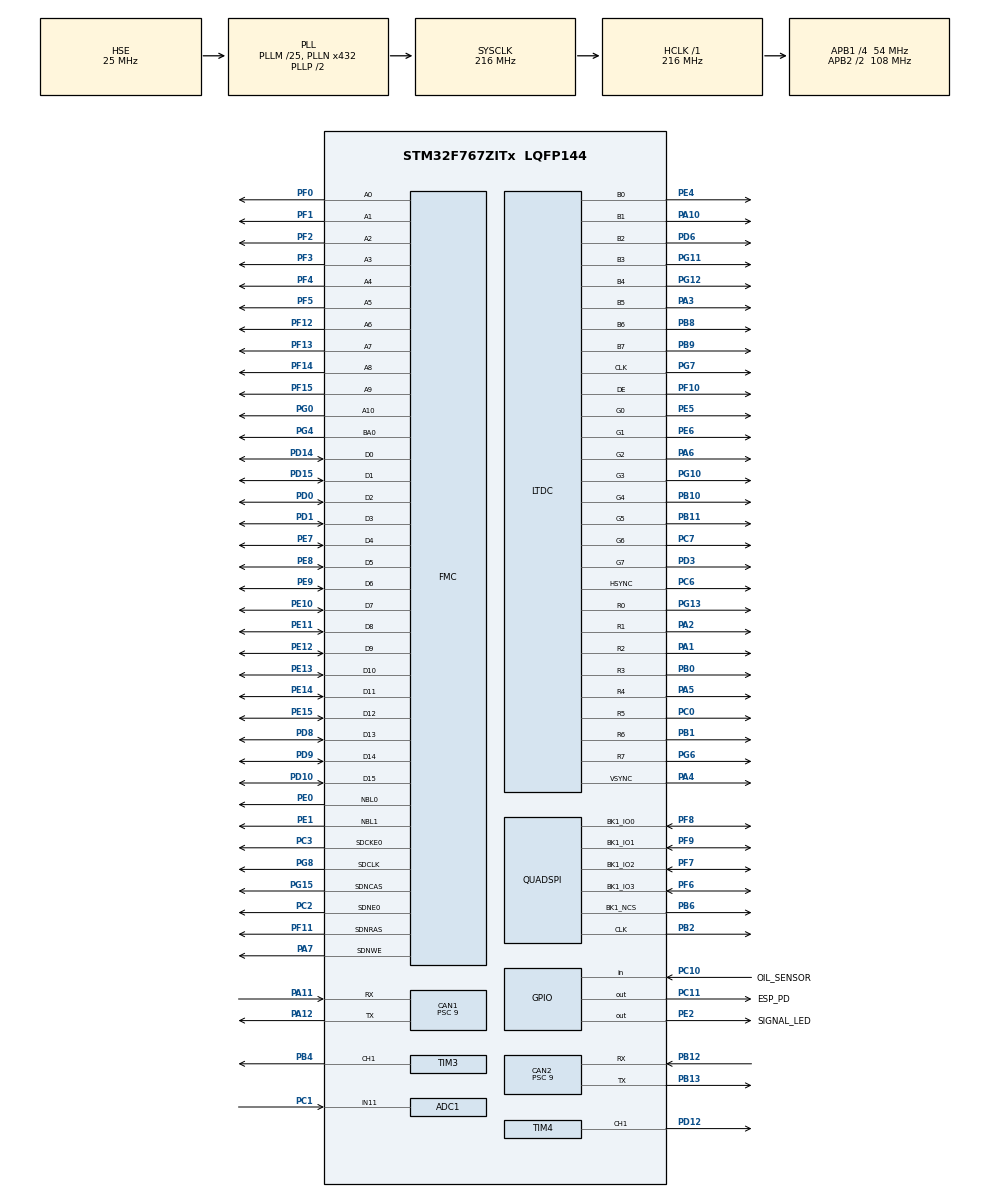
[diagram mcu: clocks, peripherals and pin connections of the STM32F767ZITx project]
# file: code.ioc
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ADC1.Channel-0\#ChannelRegularConversion=ADC_CHANNEL_11
ADC1.ClockPrescaler=ADC_CLOCK_SYNC_PCLK_DIV4
ADC1.ContinuousConvMode=DISABLE
ADC1.EnableAnalogWatchDog=false
ADC1.NbrOfConversion=1
ADC1.NbrOfConversionFlag=1
ADC1.Rank-0\#ChannelRegularConversion=1
ADC1.SamplingTime-0\#ChannelRegularConversion=ADC_SAMPLETIME_480CYCLES
ADC1.ScanConvMode=ADC_SCAN_DISABLE
ADC1.master=1
CAN1.BS1=CAN_BS1_2TQ
CAN1.BS2=CAN_BS2_3TQ
CAN1.CalculateBaudRate=999999
CAN1.CalculateTimeBit=1000
CAN1.CalculateTimeQuantum=166.66666666666669
CAN1.NART=ENABLE
CAN1.Prescaler=9
CAN2.BS1=CAN_BS1_2TQ
CAN2.BS2=CAN_BS2_3TQ
CAN2.CalculateBaudRate=999999
CAN2.CalculateTimeBit=1000
CAN2.CalculateTimeQuantum=166.66666666666669
CAN2.NART=ENABLE
CAN2.Prescaler=9
CAN2.SJW=CAN_SJW_2TQ
CORTEX_M7.CPU_DCache=Enabled
CORTEX_M7.CPU_ICache=Enabled
DMA2D.ColorMode=DMA2D_OUTPUT_RGB888
Dma.Request0=TIM4_CH1
Dma.Request1=TIM3_CH1/TRIG
Dma.TIM3_CH1/TRIG.1.Direction=DMA_MEMORY_TO_PERIPH
Dma.TIM3_CH1/TRIG.1.FIFOMode=DMA_FIFOMODE_DISABLE
Dma.TIM3_CH1/TRIG.1.Instance=DMA1_Stream4
Dma.TIM3_CH1/TRIG.1.MemDataAlignment=DMA_MDATAALIGN_HALFWORD
Dma.TIM3_CH1/TRIG.1.MemInc=DMA_MINC_ENABLE
Dma.TIM3_CH1/TRIG.1.Mode=DMA_NORMAL
Dma.TIM3_CH1/TRIG.1.PeriphDataAlignment=DMA_PDATAALIGN_HALFWORD
Dma.TIM3_CH1/TRIG.1.PeriphInc=DMA_PINC_DISABLE
Dma.TIM3_CH1/TRIG.1.Priority=DMA_PRIORITY_LOW
Dma.TIM4_CH1.0.Direction=DMA_MEMORY_TO_PERIPH
Dma.TIM4_CH1.0.FIFOMode=DMA_FIFOMODE_DISABLE
Dma.TIM4_CH1.0.Instance=DMA1_Stream0
Dma.TIM4_CH1.0.MemDataAlignment=DMA_MDATAALIGN_HALFWORD
Dma.TIM4_CH1.0.MemInc=DMA_MINC_ENABLE
Dma.TIM4_CH1.0.Mode=DMA_NORMAL
Dma.TIM4_CH1.0.PeriphDataAlignment=DMA_PDATAALIGN_HALFWORD
Dma.TIM4_CH1.0.PeriphInc=DMA_PINC_DISABLE
Dma.TIM4_CH1.0.Priority=DMA_PRIORITY_LOW
FMC.CASLatency1=FMC_SDRAM_CAS_LATENCY_2
FMC.ExitSelfRefreshDelay1=7
FMC.LoadToActiveDelay1=2
FMC.RCDDelay1=2
FMC.RPDelay1=2
FMC.RPDelay2=2
FMC.ReadBurst1=FMC_SDRAM_RBURST_ENABLE
FMC.ReadBurst2=FMC_SDRAM_RBURST_ENABLE
FMC.RowCycleDelay1=6
FMC.RowCycleDelay2=6
FMC.SDClockPeriod1=FMC_SDRAM_CLOCK_PERIOD_2
FMC.SDClockPeriod2=FMC_SDRAM_CLOCK_PERIOD_2
FMC.SelfRefreshTime1=4
FMC.WriteProtection1=FMC_SDRAM_WRITE_PROTECTION_DISABLE
FMC.WriteRecoveryTime1=3
FREERTOS.Tasks01=hardwareTASK,32,512,StartHardwareTask,Default,NULL,Dynamic,NULL,NULL;touchGFXTask,24,32768,StartTouchGFXTask,Default,NULL,Dynamic,NULL,NULL;infoLed,8,128,StartInfoLed,Default,NULL,Dynamic,NULL,NULL;displayBackligh,8,128,StartDisplayBacklight,Default,NULL,Dynamic,NULL,NULL;fuelConsumption,24,128,StartComputeFuelConsumption,Default,NULL,Dynamic,NULL,NULL
FREERTOS.configENABLE_FPU=1
FREERTOS.configLIBRARY_MAX_SYSCALL_INTERRUPT_PRIORITY=3
FREERTOS.configTOTAL_HEAP_SIZE=204800
LTDC.ActiveH=480
LTDC.ActiveW=800
LTDC.Alpha0_L0=0
LTDC.Alpha_L0=255
LTDC.FBStartAdress_L0=0xC0000000
LTDC.HBP=8
LTDC.HFP=8
LTDC.HSync=4
LTDC.ImageHeight_L0=480
LTDC.ImageWidth_L0=800
LTDC.Layers=0
LTDC.PixelFormat_L0=LTDC_PIXEL_FORMAT_RGB888
LTDC.VBP=8
LTDC.VFP=8
LTDC.VSync=40
LTDC.WindowX1_L0=800
LTDC.WindowY1_L0=480
Mcu.Family=STM32F7
Mcu.Name=STM32F767ZITx
Mcu.Package=LQFP144
NVIC.CAN1_RX0_IRQn=true\:3\:0\:false\:false\:true\:true\:true\:true
NVIC.CAN2_RX0_IRQn=true\:3\:0\:false\:false\:true\:true\:true\:true
NVIC.DMA1_Stream0_IRQn=true\:3\:0\:false\:false\:true\:true\:false\:true
NVIC.DMA1_Stream4_IRQn=true\:3\:0\:false\:false\:true\:true\:false\:true
NVIC.DMA2D_IRQn=true\:3\:0\:false\:false\:true\:true\:true\:true
NVIC.LTDC_IRQn=true\:3\:0\:false\:false\:true\:true\:true\:true
NVIC.PriorityGroup=NVIC_PRIORITYGROUP_4
NVIC.QUADSPI_IRQn=true\:3\:0\:false\:false\:true\:true\:true\:true
NVIC.TIM6_DAC_IRQn=true\:15\:0\:false\:false\:true\:false\:false\:true
NVIC.TimeBase=TIM6_DAC_IRQn
NVIC.TimeBaseIP=TIM6
PA1.GPIO_Speed=GPIO_SPEED_FREQ_LOW
PA1.Mode=RGB888
PA1.Signal=LTDC_R2
PA10.GPIO_Speed=GPIO_SPEED_FREQ_LOW
PA10.Mode=RGB888
PA10.Signal=LTDC_B1
PA11.Mode=CAN_Activate
PA11.Signal=CAN1_RX
PA12.Mode=CAN_Activate
PA12.Signal=CAN1_TX
PA13.Mode=Trace_Asynchronous_SW
PA13.Signal=SYS_JTMS-SWDIO
PA14.Mode=Trace_Asynchronous_SW
PA14.Signal=SYS_JTCK-SWCLK
PA2.GPIO_Speed=GPIO_SPEED_FREQ_LOW
PA2.Mode=RGB888
PA2.Signal=LTDC_R1
PA3.GPIO_Speed=GPIO_SPEED_FREQ_LOW
PA3.Mode=RGB888
PA3.Signal=LTDC_B5
PA4.GPIO_Speed=GPIO_SPEED_FREQ_LOW
PA4.Mode=RGB888
PA4.Signal=LTDC_VSYNC
PA5.GPIO_Speed=GPIO_SPEED_FREQ_LOW
PA5.Mode=RGB888
PA5.Signal=LTDC_R4
PA6.GPIO_Speed=GPIO_SPEED_FREQ_LOW
PA6.Mode=RGB888
PA6.Signal=LTDC_G2
PA7.Signal=FMC_SDNWE
PB0.GPIO_Speed=GPIO_SPEED_FREQ_LOW
PB0.Mode=RGB888
PB0.Signal=LTDC_R3
PB1.GPIO_Speed=GPIO_SPEED_FREQ_LOW
PB1.Mode=RGB888
PB1.Signal=LTDC_R6
PB10.GPIO_Speed=GPIO_SPEED_FREQ_LOW
PB10.Mode=RGB888
PB10.Signal=LTDC_G4
PB11.GPIO_Speed=GPIO_SPEED_FREQ_LOW
PB11.Mode=RGB888
PB11.Signal=LTDC_G5
PB12.Mode=CAN_Activate
PB12.Signal=CAN2_RX
PB13.Mode=CAN_Activate
PB13.Signal=CAN2_TX
PB2.Mode=Single Bank 1
PB2.Signal=QUADSPI_CLK
PB3.Mode=Trace_Asynchronous_SW
PB3.Signal=SYS_JTDO-SWO
PB4.Signal=S_TIM3_CH1
PB6.Mode=Single Bank 1
PB6.Signal=QUADSPI_BK1_NCS
PB8.GPIO_Speed=GPIO_SPEED_FREQ_LOW
PB8.Mode=RGB888
PB8.Signal=LTDC_B6
PB9.GPIO_Speed=GPIO_SPEED_FREQ_LOW
PB9.Mode=RGB888
PB9.Signal=LTDC_B7
PC0.GPIO_Speed=GPIO_SPEED_FREQ_LOW
PC0.Mode=RGB888
PC0.Signal=LTDC_R5
PC1.Signal=ADCx_IN11
PC10.GPIO_Label=OIL_SENSOR
PC10.GPIO_PuPd=GPIO_PULLUP
PC10.Signal=GPIO_Input
PC11.GPIO_Label=ESP_PD
PC11.Signal=GPIO_Output
PC2.Mode=SdramChipSelect1_1
PC2.Signal=FMC_SDNE0
PC3.Mode=SdramChipSelect1_1
PC3.Signal=FMC_SDCKE0
PC6.GPIO_Speed=GPIO_SPEED_FREQ_LOW
PC6.Mode=RGB888
PC6.Signal=LTDC_HSYNC
PC7.GPIO_Speed=GPIO_SPEED_FREQ_LOW
PC7.Mode=RGB888
PC7.Signal=LTDC_G6
PD0.GPIO_PuPd=GPIO_NOPULL
PD0.Signal=FMC_D2_DA2
PD1.GPIO_PuPd=GPIO_NOPULL
PD1.Signal=FMC_D3_DA3
PD10.GPIO_PuPd=GPIO_NOPULL
PD10.Signal=FMC_D15_DA15
PD12.Signal=S_TIM4_CH1
PD14.GPIO_PuPd=GPIO_NOPULL
PD14.Signal=FMC_D0_DA0
PD15.GPIO_PuPd=GPIO_NOPULL
PD15.Signal=FMC_D1_DA1
PD3.GPIO_Speed=GPIO_SPEED_FREQ_LOW
PD3.Mode=RGB888
PD3.Signal=LTDC_G7
PD6.GPIO_Speed=GPIO_SPEED_FREQ_LOW
PD6.Mode=RGB888
PD6.Signal=LTDC_B2
PD8.GPIO_PuPd=GPIO_NOPULL
PD8.Signal=FMC_D13_DA13
PD9.GPIO_PuPd=GPIO_NOPULL
PD9.Signal=FMC_D14_DA14
PE0.GPIO_PuPd=GPIO_NOPULL
PE0.Signal=FMC_NBL0
PE1.GPIO_PuPd=GPIO_NOPULL
PE1.Signal=FMC_NBL1
PE10.GPIO_PuPd=GPIO_NOPULL
PE10.Signal=FMC_D7_DA7
PE11.GPIO_PuPd=GPIO_NOPULL
PE11.Signal=FMC_D8_DA8
PE12.GPIO_PuPd=GPIO_NOPULL
PE12.Signal=FMC_D9_DA9
PE13.GPIO_PuPd=GPIO_NOPULL
PE13.Signal=FMC_D10_DA10
PE14.GPIO_PuPd=GPIO_NOPULL
PE14.Signal=FMC_D11_DA11
PE15.GPIO_PuPd=GPIO_NOPULL
PE15.Signal=FMC_D12_DA12
PE2.GPIO_Label=SIGNAL_LED
PE2.Signal=GPIO_Output
PE4.GPIO_Speed=GPIO_SPEED_FREQ_LOW
PE4.Mode=RGB888
PE4.Signal=LTDC_B0
PE5.GPIO_Speed=GPIO_SPEED_FREQ_LOW
PE5.Mode=RGB888
PE5.Signal=LTDC_G0
PE6.GPIO_Speed=GPIO_SPEED_FREQ_LOW
PE6.Mode=RGB888
PE6.Signal=LTDC_G1
PE7.GPIO_PuPd=GPIO_NOPULL
PE7.Signal=FMC_D4_DA4
PE8.GPIO_PuPd=GPIO_NOPULL
PE8.Signal=FMC_D5_DA5
PE9.GPIO_PuPd=GPIO_NOPULL
PE9.Signal=FMC_D6_DA6
PF0.Signal=FMC_A0
PF1.Signal=FMC_A1
PF10.GPIO_Speed=GPIO_SPEED_FREQ_LOW
PF10.Mode=RGB888
PF10.Signal=LTDC_DE
PF11.Signal=FMC_SDNRAS
PF12.Signal=FMC_A6
PF13.Signal=FMC_A7
PF14.Signal=FMC_A8
PF15.Signal=FMC_A9
PF2.Signal=FMC_A2
PF3.Signal=FMC_A3
PF4.Signal=FMC_A4
PF5.Signal=FMC_A5
PF6.Mode=Single Bank 1
PF6.Signal=QUADSPI_BK1_IO3
PF7.Mode=Single Bank 1
PF7.Signal=QUADSPI_BK1_IO2
PF8.Mode=Single Bank 1
PF8.Signal=QUADSPI_BK1_IO0
PF9.Mode=Single Bank 1
PF9.Signal=QUADSPI_BK1_IO1
PG0.Signal=FMC_A10
PG10.GPIO_Speed=GPIO_SPEED_FREQ_LOW
PG10.Mode=RGB888
PG10.Signal=LTDC_G3
PG11.GPIO_Speed=GPIO_SPEED_FREQ_LOW
PG11.Mode=RGB888
PG11.Signal=LTDC_B3
PG12.GPIO_Speed=GPIO_SPEED_FREQ_LOW
PG12.Mode=RGB888
PG12.Signal=LTDC_B4
PG13.GPIO_Speed=GPIO_SPEED_FREQ_LOW
PG13.Mode=RGB888
PG13.Signal=LTDC_R0
PG15.Signal=FMC_SDNCAS
PG4.Signal=FMC_A14_BA0
PG6.GPIO_Speed=GPIO_SPEED_FREQ_LOW
PG6.Mode=RGB888
PG6.Signal=LTDC_R7
PG7.GPIO_Speed=GPIO_SPEED_FREQ_LOW
PG7.Mode=RGB888
PG7.Signal=LTDC_CLK
PG8.Signal=FMC_SDCLK
PH0/OSC_IN.Mode=HSE-External-Oscillator
PH0/OSC_IN.Signal=RCC_OSC_IN
PH1/OSC_OUT.Mode=HSE-External-Oscillator
PH1/OSC_OUT.Signal=RCC_OSC_OUT
ProjectManager.HeapSize=0x200
ProjectManager.StackSize=0x400
ProjectManager.TargetToolchain=STM32CubeIDE
QUADSPI.ChipSelectHighTime=QSPI_CS_HIGH_TIME_6_CYCLE
QUADSPI.ClockPrescaler=3
QUADSPI.FlashSize=23
QUADSPI.SampleShifting=QSPI_SAMPLE_SHIFTING_HALFCYCLE
RCC.AHBFreq_Value=216000000
RCC.APB1CLKDivider=RCC_HCLK_DIV4
RCC.APB1Freq_Value=54000000
RCC.APB1TimFreq_Value=108000000
RCC.APB2CLKDivider=RCC_HCLK_DIV2
RCC.APB2Freq_Value=108000000
RCC.APB2TimFreq_Value=216000000
RCC.CortexFreq_Value=216000000
RCC.HCLKFreq_Value=216000000
RCC.HSE_VALUE=25000000
RCC.HSI_VALUE=16000000
RCC.LSE_VALUE=32768
RCC.PLLM=25
RCC.PLLN=432
RCC.PLLSAIN=279
RCC.PLLSAIR=3
RCC.PLLSAIRDiv=RCC_PLLSAIDIVR_4
RCC.PLLSourceVirtual=RCC_PLLSOURCE_HSE
RCC.SYSCLKFreq_VALUE=216000000
RCC.SYSCLKSource=RCC_SYSCLKSOURCE_PLLCLK
RCC.USBFreq_Value=216000000
RCC.VCOOutputFreq_Value=432000000
SH.ADCx_IN11.0=ADC1_IN11,IN11
SH.FMC_A0.0=FMC_A0,11b-sda1
SH.FMC_A1.0=FMC_A1,11b-sda1
SH.FMC_A10.0=FMC_A10,11b-sda1
SH.FMC_A14_BA0.0=FMC_BA0,TwoSdramBanks1
SH.FMC_A2.0=FMC_A2,11b-sda1
SH.FMC_A3.0=FMC_A3,11b-sda1
SH.FMC_A4.0=FMC_A4,11b-sda1
SH.FMC_A5.0=FMC_A5,11b-sda1
SH.FMC_A6.0=FMC_A6,11b-sda1
SH.FMC_A7.0=FMC_A7,11b-sda1
SH.FMC_A8.0=FMC_A8,11b-sda1
SH.FMC_A9.0=FMC_A9,11b-sda1
SH.FMC_D0_DA0.0=FMC_D0,sd-16b-d1
SH.FMC_D10_DA10.0=FMC_D10,sd-16b-d1
SH.FMC_D11_DA11.0=FMC_D11,sd-16b-d1
SH.FMC_D12_DA12.0=FMC_D12,sd-16b-d1
SH.FMC_D13_DA13.0=FMC_D13,sd-16b-d1
SH.FMC_D14_DA14.0=FMC_D14,sd-16b-d1
SH.FMC_D15_DA15.0=FMC_D15,sd-16b-d1
SH.FMC_D1_DA1.0=FMC_D1,sd-16b-d1
SH.FMC_D2_DA2.0=FMC_D2,sd-16b-d1
SH.FMC_D3_DA3.0=FMC_D3,sd-16b-d1
SH.FMC_D4_DA4.0=FMC_D4,sd-16b-d1
SH.FMC_D5_DA5.0=FMC_D5,sd-16b-d1
SH.FMC_D6_DA6.0=FMC_D6,sd-16b-d1
SH.FMC_D7_DA7.0=FMC_D7,sd-16b-d1
SH.FMC_D8_DA8.0=FMC_D8,sd-16b-d1
SH.FMC_D9_DA9.0=FMC_D9,sd-16b-d1
SH.FMC_NBL0.0=FMC_NBL0,Sd2ByteEnable1
SH.FMC_NBL1.0=FMC_NBL1,Sd2ByteEnable1
SH.FMC_SDCLK.0=FMC_SDCLK,11b-sda1
SH.FMC_SDNCAS.0=FMC_SDNCAS,11b-sda1
SH.FMC_SDNRAS.0=FMC_SDNRAS,11b-sda1
SH.FMC_SDNWE.0=FMC_SDNWE,11b-sda1
SH.S_TIM3_CH1.0=TIM3_CH1,PWM Generation1 CH1
SH.S_TIM4_CH1.0=TIM4_CH1,PWM Generation1 CH1
STMicroelectronics.X-CUBE-TOUCHGFX.4.17.0.ApplicationCcGraphicsJjApplication=TouchGFXOoGenerator
STMicroelectronics.X-CUBE-TOUCHGFX.4.17.0.tgfx_address1=0xC0000000
STMicroelectronics.X-CUBE-TOUCHGFX.4.17.0.tgfx_address2=0xC0120000
STMicroelectronics.X-CUBE-TOUCHGFX.4.17.0.tgfx_buffering_strategy=Single
STMicroelectronics.X-CUBE-TOUCHGFX.4.17.0.tgfx_custom_height=480
STMicroelectronics.X-CUBE-TOUCHGFX.4.17.0.tgfx_display_interface=disp_ltdc
STMicroelectronics.X-CUBE-TOUCHGFX.4.17.0.tgfx_hardware_accelerator=dma_2d
STMicroelectronics.X-CUBE-TOUCHGFX.4.17.0.tgfx_location=By Address
STMicroelectronics.X-CUBE-TOUCHGFX.4.17.0.tgfx_oswrapper=CMSIS V2
STMicroelectronics.X-CUBE-TOUCHGFX.4.17.0.tgfx_vsync=vsync_ltdc
STMicroelectronics.X-CUBE-TOUCHGFX.4.17.0_IsPackSelfContextualization=true
TIM3.Channel-PWM\ Generation1\ CH1=TIM_CHANNEL_1
TIM3.ClockDivision=TIM_CLOCKDIVISION_DIV1
TIM3.OCMode_PWM-PWM\ Generation1\ CH1=TIM_OCMODE_PWM1
TIM3.Period=134
TIM3.Prescaler=0
TIM3.TIM_MasterOutputTrigger=TIM_TRGO_RESET
TIM4.Channel-PWM\ Generation1\ CH1=TIM_CHANNEL_1
TIM4.Period=215
TIM4.Pulse-PWM\ Generation1\ CH1=0
VP_CRC_VS_CRC.Mode=CRC_Activate
VP_DMA2D_VS_DMA2D.Mode=DMA2D_Activate
VP_FREERTOS_VS_CMSIS_V2.Mode=CMSIS_V2
VP_STMicroelectronics.X-CUBE-TOUCHGFX_VS_GraphicsJjApplication_4.17.0.Mode=GraphicsJjApplication
VP_SYS_VS_tim6.Mode=TIM6
VP_TIM3_VS_ClockSourceINT.Mode=Internal
VP_TIM4_VS_ClockSourceINT.Mode=Internal
board=custom

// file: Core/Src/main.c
/* USER CODE BEGIN Header */
/**
  ******************************************************************************
  * @file           : main.c
  * @brief          : Main program body
  ******************************************************************************
  * @attention
  *
  * <h2><center>&copy; Copyright (c) 2021 STMicroelectronics.
  * All rights reserved.</center></h2>
  *
  * This software component is licensed by ST under Ultimate Liberty license
  * SLA0044, the "License"; You may not use this file except in compliance with
  * the License. You may obtain a copy of the License at:
  *                             www.st.com/SLA0044
  *
  ******************************************************************************
  */
/* USER CODE END Header */
#include "main.h"
#include "cmsis_os.h"
#include "adc.h"
#include "can.h"
#include "crc.h"
#include "dma.h"
#include "dma2d.h"
#include "ltdc.h"
#include "quadspi.h"
#include "tim.h"
#include "gpio.h"
#include "fmc.h"
#include "app_touchgfx.h"

/* USER CODE BEGIN Includes */
#include "at25sf128a.h"
#include "ecumaster.h"
#include "WS2812_driver.h"
/* USER CODE END Includes */

void SystemClock_Config(void);
void MX_FREERTOS_Init(void);

int main(void)
{

  /* Enable I-Cache---------------------------------------------------------*/
  SCB_EnableICache();

  /* Enable D-Cache---------------------------------------------------------*/
  SCB_EnableDCache();

  /* MCU Configuration--------------------------------------------------------*/

  /* Reset of all peripherals, Initializes the Flash interface and the Systick. */
  HAL_Init();

  /* Configure the system clock */
  SystemClock_Config();

  /* Initialize all configured peripherals */
  MX_GPIO_Init();
  MX_CRC_Init();
  MX_FMC_Init();
  MX_QUADSPI_Init();
  MX_LTDC_Init();
  MX_DMA2D_Init();
  MX_CAN2_Init();
  MX_CAN1_Init();
  MX_DMA_Init();
  MX_TIM3_Init();
  MX_TIM4_Init();
  MX_ADC1_Init();
  MX_TouchGFX_Init();
  /* USER CODE BEGIN 2 */
  FLASH_QSPI_Init();
  /* USER CODE END 2 */

  /* Init scheduler */
  osKernelInitialize();  /* Call init function for freertos objects (in freertos.c) */
  MX_FREERTOS_Init();
  /* Start scheduler */
  osKernelStart();

  /* We should never get here as control is now taken by the scheduler */
  /* Infinite loop */
  while (1)
  {

  }
}

void SystemClock_Config(void)
{
  RCC_OscInitTypeDef RCC_OscInitStruct = {0};
  RCC_ClkInitTypeDef RCC_ClkInitStruct = {0};

  /** Configure the main internal regulator output voltage
  */
  __HAL_RCC_PWR_CLK_ENABLE();
  __HAL_PWR_VOLTAGESCALING_CONFIG(PWR_REGULATOR_VOLTAGE_SCALE1);
  /** Initializes the RCC Oscillators according to the specified parameters
  * in the RCC_OscInitTypeDef structure.
  */
  RCC_OscInitStruct.OscillatorType = RCC_OSCILLATORTYPE_HSE;
  RCC_OscInitStruct.HSEState = RCC_HSE_ON;
  RCC_OscInitStruct.PLL.PLLState = RCC_PLL_ON;
  RCC_OscInitStruct.PLL.PLLSource = RCC_PLLSOURCE_HSE;
  RCC_OscInitStruct.PLL.PLLM = 25;
  RCC_OscInitStruct.PLL.PLLN = 432;
  RCC_OscInitStruct.PLL.PLLP = RCC_PLLP_DIV2;
  RCC_OscInitStruct.PLL.PLLQ = 2;
  RCC_OscInitStruct.PLL.PLLR = 2;
  if (HAL_RCC_OscConfig(&RCC_OscInitStruct) != HAL_OK)
  {
    Error_Handler();
  }
  /** Activate the Over-Drive mode
  */
  if (HAL_PWREx_EnableOverDrive() != HAL_OK)
  {
    Error_Handler();
  }
  /** Initializes the CPU, AHB and APB buses clocks
  */
  RCC_ClkInitStruct.ClockType = RCC_CLOCKTYPE_HCLK|RCC_CLOCKTYPE_SYSCLK
                              |RCC_CLOCKTYPE_PCLK1|RCC_CLOCKTYPE_PCLK2;
  RCC_ClkInitStruct.SYSCLKSource = RCC_SYSCLKSOURCE_PLLCLK;
  RCC_ClkInitStruct.AHBCLKDivider = RCC_SYSCLK_DIV1;
  RCC_ClkInitStruct.APB1CLKDivider = RCC_HCLK_DIV4;
  RCC_ClkInitStruct.APB2CLKDivider = RCC_HCLK_DIV2;

  if (HAL_RCC_ClockConfig(&RCC_ClkInitStruct, FLASH_LATENCY_7) != HAL_OK)
  {
    Error_Handler();
  }
}

void HAL_TIM_PeriodElapsedCallback(TIM_HandleTypeDef *htim)
{
  if (htim->Instance == TIM6) {
    HAL_IncTick();
  }
}

void Error_Handler(void)
{
  __disable_irq();
  while (1)
  {
  }
}

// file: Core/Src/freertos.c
/* USER CODE BEGIN Header */
/**
 ******************************************************************************
 * File Name          : freertos.c
 * Description        : Code for freertos applications
 ******************************************************************************
 * @attention
 *
 * Copyright (c) 2022 STMicroelectronics.
 * All rights reserved.
 *
 * This software is licensed under terms that can be found in the LICENSE file
 * in the root directory of this software component.
 * If no LICENSE file comes with this software, it is provided AS-IS.
 *
 ******************************************************************************
 */
/* USER CODE END Header */

#include "FreeRTOS.h"
#include "task.h"
#include "main.h"
#include "cmsis_os.h"

/* USER CODE BEGIN Includes */
#include "adc.h"
#include "app_touchgfx.h"
#include "can.h"
#include "gpio.h"
#include "tim.h"
#include "WS2812_driver.h"
#include "ecumaster.h"
#include "display_setup.h"
#include "telemetry_data.h"
#include <math.h>

/* USER CODE END Includes */

/* USER CODE BEGIN PD */
#define PWM_CHANGE 5
/* USER CODE END PD */

/* Definitions for hardwareTASK */
osThreadId_t hardwareTASKHandle;
const osThreadAttr_t hardwareTASK_attributes =
{ .name = "hardwareTASK", .stack_size = 512 * 4, .priority =
		(osPriority_t) osPriorityAboveNormal, };
/* Definitions for touchGFXTask */
osThreadId_t touchGFXTaskHandle;
const osThreadAttr_t touchGFXTask_attributes =
{ .name = "touchGFXTask", .stack_size = 32768 * 4, .priority =
		(osPriority_t) osPriorityNormal, };
/* Definitions for infoLed */
osThreadId_t infoLedHandle;
const osThreadAttr_t infoLed_attributes =
{ .name = "infoLed", .stack_size = 128 * 4, .priority =
		(osPriority_t) osPriorityLow, };
/* Definitions for displayBackligh */
osThreadId_t displayBacklighHandle;
const osThreadAttr_t displayBackligh_attributes =
{ .name = "displayBackligh", .stack_size = 128 * 4, .priority =
		(osPriority_t) osPriorityLow, };
/* Definitions for fuelConsumption */
osThreadId_t fuelConsumptionHandle;
const osThreadAttr_t fuelConsumption_attributes =
{ .name = "fuelConsumption", .stack_size = 128 * 4, .priority =
		(osPriority_t) osPriorityNormal, };

void StartHardwareTask(void *argument);
void StartTouchGFXTask(void *argument);
void StartInfoLed(void *argument);
void StartDisplayBacklight(void *argument);
void StartComputeFuelConsumption(void *argument);

void MX_FREERTOS_Init(void); /* (MISRA C 2004 rule 8.1) */

void MX_FREERTOS_Init(void)
{

	/* Create the thread(s) */
	/* creation of hardwareTASK */
	hardwareTASKHandle = osThreadNew(StartHardwareTask, NULL,
			&hardwareTASK_attributes);

	/* creation of touchGFXTask */
	touchGFXTaskHandle = osThreadNew(StartTouchGFXTask, NULL,
			&touchGFXTask_attributes);

	/* creation of infoLed */
	infoLedHandle = osThreadNew(StartInfoLed, NULL, &infoLed_attributes);

	/* creation of displayBackligh */
	displayBacklighHandle = osThreadNew(StartDisplayBacklight, NULL,
			&displayBackligh_attributes);

	/* creation of fuelConsumption */
	fuelConsumptionHandle = osThreadNew(StartComputeFuelConsumption, NULL,
			&fuelConsumption_attributes);

}

void StartHardwareTask(void *argument)
{
	/* USER CODE BEGIN StartHardwareTask */
	HAL_CAN_Start(&hcan2);
	HAL_CAN_Start(&hcan1);

	HAL_CAN_ActivateNotification(&hcan2, CAN_IT_RX_FIFO0_MSG_PENDING);
	HAL_CAN_ActivateNotification(&hcan1, CAN_IT_RX_FIFO0_MSG_PENDING);

	WS2812_Init();
	ComputeOptimalPoints();

	osDelay(150);
	uint8_t ledMode = displaySetup.ledBarMode;
	/* Infinite loop */
	for (;;)
	{

		telemetryData.oilPress = HAL_GPIO_ReadPin(OIL_SENSOR_GPIO_Port,
				OIL_SENSOR_Pin);
		if (telemetryData.gear == 0)
		{
			////HAL_GPIO_WritePin(NEUTRAL_LED_GPIO_Port, NEUTRAL_LED_Pin, SET);
			ledMode = 0;
		}
		else
		{
			//HAL_GPIO_WritePin(NEUTRAL_LED_GPIO_Port, NEUTRAL_LED_Pin, RESET);
			ledMode = displaySetup.ledBarMode;
		}
		updateLeds(EcuData.rpm, ledMode);

		osDelay(100);
		/* BURNED FUEL TRANSMISSION */
		uint16_t burnedFuel = (uint16_t)telemetryData.burnedFuel* 0x2000;
		uint8_t RxData[2];
		RxData[0] = burnedFuel%0xFF;
		RxData[1] = burnedFuel / 0xFF;
		 CAN_TxHeaderTypeDef TxHeader;
		 TxHeader.DLC = 2;
		 TxHeader.IDE = CAN_ID_STD;
		 TxHeader.RTR = CAN_RTR_DATA;
		 TxHeader.StdId = 0x1FE;

		// HAL_CAN_AddTxMessage(INTERNAL_CAN, &TxHeader, RxData, &TxMailbox);
		 HAL_CAN_AddTxMessage(&hcan2, &TxHeader, RxData, &TxMailbox);
		if (telemetryData.steeringWheelAttached == 1
				&& HAL_GetTick() - telemetryData.steeringWheelAttachedTimestamp
						> 2000)
		{
			telemetryData.steeringWheelAttached = 0;
		}
	}
	/* USER CODE END StartHardwareTask */
}

void StartTouchGFXTask(void *argument)
{
	/* USER CODE BEGIN StartTouchGFXTask */
	MX_TouchGFX_Process();
	/* Infinite loop */
	for (;;)
	{
		osDelay(1);
	}
	/* USER CODE END StartTouchGFXTask */
}

void StartInfoLed(void *argument)
{
	/* USER CODE BEGIN StartInfoLed */
	/* Infinite loop */
	for (;;)
	{
		osDelay(250);
		HAL_GPIO_TogglePin(SIGNAL_LED_GPIO_Port, SIGNAL_LED_Pin);
		// HAL_IWDG_Refresh(&hiwdg);
	}
	/* USER CODE END StartInfoLed */
}

void StartDisplayBacklight(void *argument)
{
	/* USER CODE BEGIN StartDisplayBacklight */

	// current set point in mA
	uint8_t setPoint = displaySetup.brightness * 1.5f;
	HAL_TIM_PWM_Start(&htim4, TIM_CHANNEL_1);
	uint8_t PWM_Pulse = 0;
	uint8_t PWM_PulseChange = 0;
	float voltage = 0.0f;
	float current = 0.0f;
	uint8_t delay = 0;
	osDelay(250);
	/* Infinite loop */
	for (;;)
	{
		HAL_ADC_Start(&hadc1);
		HAL_ADC_PollForConversion(&hadc1, 10);

		osDelay(100 - delay);
		voltage = HAL_ADC_GetValue(&hadc1) * 3.3f / 4095.0f;
		current = voltage / 5.1f * 1000.0f;

		PWM_PulseChange = (int8_t) round((setPoint - current) / 10.0f);
		delay = 0;
		if (PWM_PulseChange > 10)
		{
			while (PWM_PulseChange > 0)
			{
				PWM_Pulse += fmin(fmin(PWM_PulseChange, PWM_CHANGE),
						215 - PWM_Pulse);
				PWM_PulseChange -= fmin(PWM_PulseChange, PWM_CHANGE);
				__HAL_TIM_SET_COMPARE(&htim4, TIM_CHANNEL_1, PWM_Pulse);
				osDelay(5);
				delay += 5;
			}

		}
		else if (PWM_PulseChange < -10)
		{
			while (PWM_PulseChange < 0)
			{
				PWM_Pulse -= fmin(fmin(PWM_PulseChange, PWM_CHANGE), PWM_Pulse);
				PWM_PulseChange -= fmax(PWM_PulseChange, -PWM_CHANGE);
				__HAL_TIM_SET_COMPARE(&htim4, TIM_CHANNEL_1, PWM_Pulse);
				osDelay(5);
				delay += 5;
			}
		}
		else
		{
			PWM_Pulse += PWM_PulseChange;
			__HAL_TIM_SET_COMPARE(&htim4, TIM_CHANNEL_1, PWM_Pulse);
		}
	}
	delay = fmax(delay, 100);
	/* USER CODE END StartDisplayBacklight */
}

void StartComputeFuelConsumption(void *argument)
{
	/* USER CODE BEGIN StartComputeFuelConsumption */
	const uint8_t injectorFuelFlow = 250; // cc / min
	static uint32_t lastComputeTime = 0;
	/* Infinite loop */
	for (;;)
	{
		float fuelUsage = ((float) EcuData.rpm / 60 / 1000) * 3
				* ((float) injectorFuelFlow / 60 / 1000) * EcuData.injPW * (lastComputeTime - HAL_GetTick());
		lastComputeTime = HAL_GetTick();
		telemetryData.burnedFuel += fuelUsage;
		osDelay(10);
	}
	/* USER CODE END StartComputeFuelConsumption */
}
